VERSION ""

NS_ :

BS_:

BU_: CONTROLLER

VAL_TABLE_ System_Status 0 "IDLE" 1 "RUNNING" 2 "ERROR" 3 "OVERCURRENT";

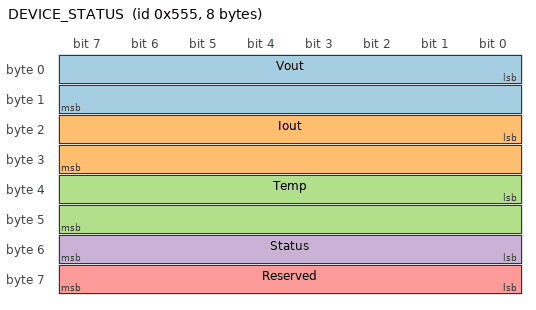
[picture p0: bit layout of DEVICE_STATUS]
BO_ 1365 DEVICE_STATUS: 8 CONTROLLER
 SG_ Vout : 0|16@1+ (0.01,0) [0|60] "V" CONTROLLER
 SG_ Iout : 16|16@1+ (0.01,0) [0|10] "A" CONTROLLER
 SG_ Temp : 32|16@1+ (0.01,0) [0|150] "°C" CONTROLLER
 SG_ Status : 48|8@1+ (1,0) [0|3] "" CONTROLLER
 SG_ Reserved : 56|8@1+ (1,0) [0|255] "" CONTROLLER

CM_ SG_ 1365 Vout "Output Voltage (scaled by 0.01V)";
CM_ SG_ 1365 Iout "Output Current (scaled by 0.01A)";
CM_ SG_ 1365 Temp "System Temperature (scaled by 0.01C)";
CM_ SG_ 1365 Status "System Status (enum: 0=IDLE, 1=RUNNING, 2=ERROR, 3=OVERCURRENT)";
